# STM32F302x8 register map
File version: 1.0
Registers are 32-bit, read-write, reset 0x0 unless marked. A register's access mark holds for its fields unless they carry their own. Offsets are from the block's base; [hi:lo] are bit positions; {n}, {i} and the like mark numbered series.

## COMP2 — Analog Comparators
Base 0x40010020; alternate view of COMP
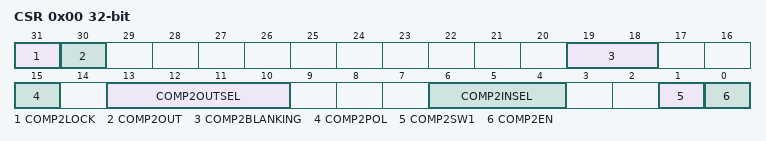
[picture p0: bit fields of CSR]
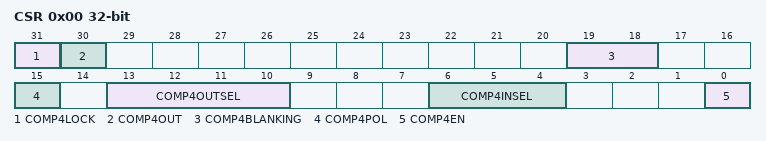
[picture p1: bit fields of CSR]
0x00 CSR — COMP control and status register
  [31] COMP2LOCK
  [30] COMP2OUT — COMP2 output level
  [19:18] COMP2BLANKING
  [15] COMP2POL — COMP2 output polarity
  [13:10] COMP2OUTSEL — COMP2 output select
  [6:4] COMP2INSEL — COMP2 inverting input select
  [1] COMP2SW1 — COMP2 SW1 switch control
  [0] COMP2EN — COMP2 enable

## COMP4 — Analog Comparators
Base 0x40010028
0x00 CSR — COMP control and status register
  [31] COMP4LOCK
  [30] COMP4OUT — COMP4 output level
  [19:18] COMP4BLANKING
  [15] COMP4POL — COMP4 output polarity
  [13:10] COMP4OUTSEL — COMP4 output select
  [6:4] COMP4INSEL — COMP4 inverting input select
  [0] COMP4EN — COMP4 enable

## COMP6 — Analog Comparators
Base 0x40010030
Registers as COMP4 (with COMP4 read as COMP6).

## OPAMP2 — Operational Amplifier (OPAMP)
Base 0x4001003C; alternate view of OPAMP
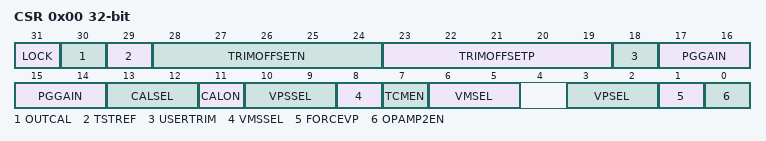
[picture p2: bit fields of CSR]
0x00 CSR — OPAMP control and status register
  [31] LOCK — OPAMP lock
  [30] OUTCAL — OPAMP output status flag
  [29] TSTREF — It enables the switch to put out the internal reference
  [28:24] TRIMOFFSETN — Offset trimming value (NMOS)
  [23:19] TRIMOFFSETP — Offset trimming value (PMOS)
  [18] USERTRIM — User trimming enable
  [17:14] PGGAIN — Gain in PGA mode
  [13:12] CALSEL — Calibration selection
  [11] CALON — Calibration mode enable
  [10:9] VPSSEL — Non inverting input secondary selection
  [8] VMSSEL — Inverting input secondary selection
  [7] TCMEN — Timer-Controlled Mux mode enable
  [6:5] VMSEL — Inverting input selection
  [3:2] VPSEL — Non inverting input selection
  [1] FORCEVP — Connect the internal references to the plus input of the OPAMPX
  [0] OPAMP2EN — OPAMP2 enable

## EXTI — External Interrupt/Event Controller
Base 0x40010400
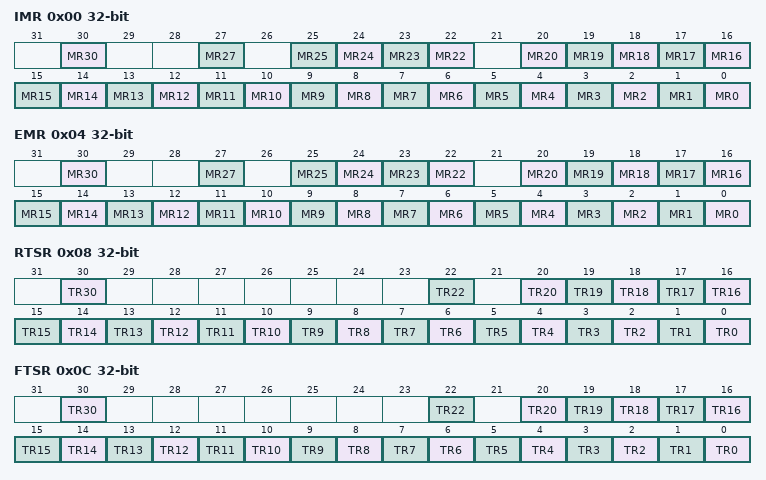
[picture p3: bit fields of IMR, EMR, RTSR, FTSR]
0x00 IMR — EXTI Interrupt mask register
  [30] MR30 — Interrupt Mask on line 30
  [27] MR27 — Interrupt Mask on line 27
  [n] MR{n} (n=22..25) — Interrupt Mask on line {n}
  [n] MR{n} (n=0..20) — Interrupt Mask on line {n}
0x00 IMR_ALT (alternate view of IMR) — EXTI Interrupt mask register
  [31:0] IM — Interrupt Mask All
0x04 EMR — EXTI Event mask register
  [30] MR30 — Event Mask on line 30
  [27] MR27 — Event Mask on line 27
  [n] MR{n} (n=22..25) — Event Mask on line {n}
  [n] MR{n} (n=0..20) — Event Mask on line {n}
0x08 RTSR — EXTI Rising trigger selection register
  [30] TR30 — Rising trigger event configuration bit of line 30
  [22] TR22 — Rising trigger event configuration bit of line 22
  [n] TR{n} (n=0..20) — Rising trigger event configuration bit of line {n}
0x0C FTSR — EXTI Falling trigger selection register
  [30] TR30 — Falling trigger event configuration bit of line 30
  [22] TR22 — Falling trigger event configuration bit of line 22
  [n] TR{n} (n=0..20) — Falling trigger event configuration bit of line {n}
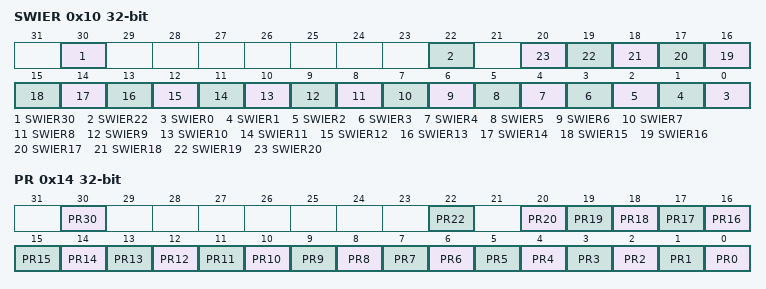
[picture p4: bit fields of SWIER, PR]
0x10 SWIER — EXTI Software interrupt event register
  [30] SWIER30 — Software Interrupt on line 30
  [22] SWIER22 — Software Interrupt on line 22
  [n] SWIER{n} (n=0..20) — Software Interrupt on line {n}
0x14 PR — EXTI Pending register
  [30] PR30 — Pending bit for line 30
  [22] PR22 — Pending bit for line 22
  [n] PR{n} (n=0..20) — Pending bit for line {n}
0x20 IMR2 — EXTI Interrupt mask register
  [0] MR32 — Interrupt Mask on line 32
0x24 EMR2 — EXTI Event mask register
  [0] MR32 — Event Mask on line 32
0x28 RTSR2 — EXTI Rising trigger selection register
  [0] TR32 — Rising trigger event configuration bit of line 32
0x2C FTSR2 — EXTI Falling trigger selection register
  [0] TR32 — Falling trigger event configuration bit of line 32
0x30 SWIER2 — EXTI Software interrupt event register
  [0] SWIER32 — Software Interrupt on line 32
0x34 PR2 — EXTI Pending register
  [0] PR32 — Pending bit for line 32
